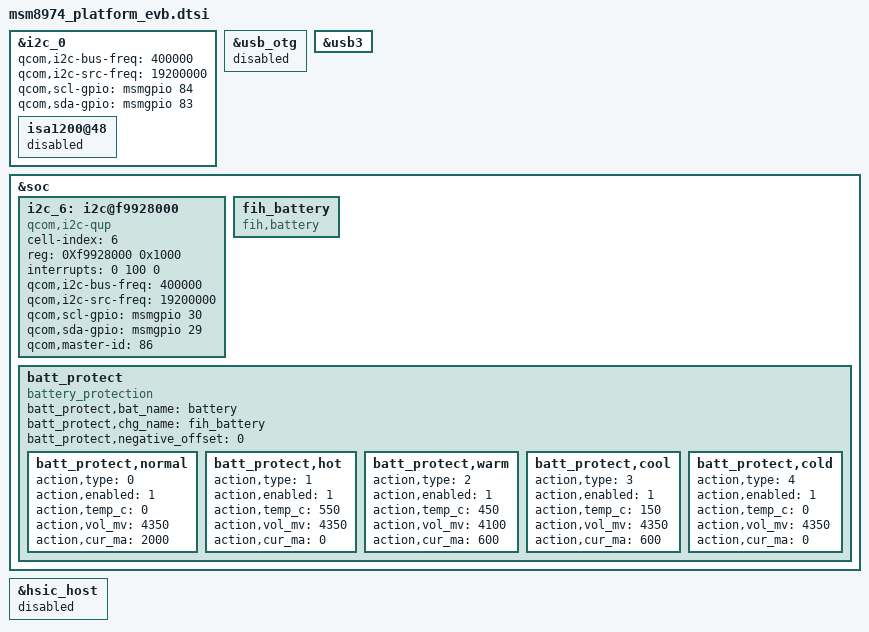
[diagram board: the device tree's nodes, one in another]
&i2c_0 {
	qcom,i2c-bus-freq = <400000>;
	qcom,i2c-src-freq = <19200000>;
	qcom,scl-gpio = <&msmgpio 84 0>;
	qcom,sda-gpio = <&msmgpio 83 0>;
	status = "okay";

	isa1200@48 {
		status = "disabled";
		compatible = "";
	};
};

&usb_otg {
	status = "disabled";
};

&usb3 {
	status = "okay";
};

&soc {
	i2c_6: i2c@f9928000 { /* BLSP#6 */
		cell-index = <6>;
		compatible = "qcom,i2c-qup";
		reg = <0Xf9928000 0x1000>;
		#address-cells = <1>;
		#size-cells = <0>;
		reg-names = "qup_phys_addr";
		interrupts = <0 100 0>;
		interrupt-names = "qup_err_intr";
		qcom,i2c-bus-freq = <400000>;
		qcom,i2c-src-freq = <19200000>;
		qcom,scl-gpio = <&msmgpio 30 0>;
		qcom,sda-gpio = <&msmgpio 29 0>;
                qcom,master-id = <86>;
		status = "okay";
	};

	fih_battery {
		status = "okay";
		compatible = "fih,battery";
	};

	batt_protect {
		status = "okay";
		compatible = "battery_protection";
		batt_protect,bat_name = "battery";
		batt_protect,chg_name = "fih_battery";
		batt_protect,negative_offset = <0>;
		batt_protect,normal {
			action,type = <0>;
			action,enabled = <1>;
			action,temp_c = <0>;
			action,vol_mv = <4350>;
			action,cur_ma = <2000>;
		};
		batt_protect,hot {
			action,type = <1>;
			action,enabled = <1>;
			action,temp_c = <550>;
			action,vol_mv = <4350>;
			action,cur_ma = <0>;
		};
		batt_protect,warm {
			action,type = <2>;
			action,enabled = <1>;
			action,temp_c = <450>;
			action,vol_mv = <4100>;
			action,cur_ma = <600>;
		};
		batt_protect,cool {
			action,type = <3>;
			action,enabled = <1>;
			action,temp_c = <150>;
			action,vol_mv = <4350>;
			action,cur_ma = <600>;
		};
		batt_protect,cold {
			action,type = <4>;
			action,enabled = <1>;
			action,temp_c = <0>;
			action,vol_mv = <4350>;
			action,cur_ma = <0>;
		};
	};
};

&hsic_host {
	status = "disabled";
};
